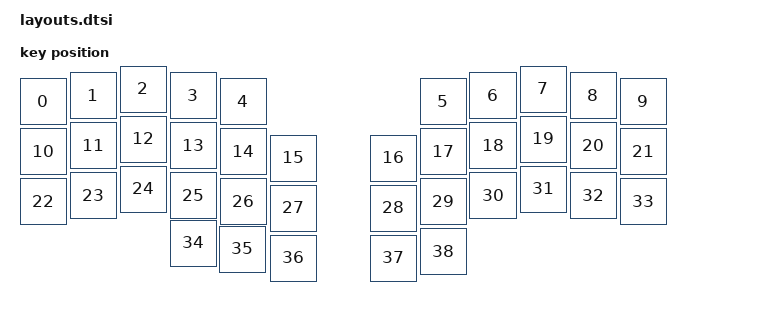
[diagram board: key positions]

#include <physical_layouts.dtsi>
/ {
    physical_layout0: physical_layout0 {
        compatible = "zmk,physical-layout";
        display-name = "Layout";
        keys
            = <&key_physical_attrs 100 100 (-50) 25 0 0 0>
			,<&key_physical_attrs 100 100 50 13 0 0 0>
			,<&key_physical_attrs 100 100 150 0 0 0 0>
			,<&key_physical_attrs 100 100 250 13 0 0 0>
			,<&key_physical_attrs 100 100 350 25 0 0 0>
			,<&key_physical_attrs 100 100 750 25 0 0 0>
			,<&key_physical_attrs 100 100 850 13 0 0 0>
			,<&key_physical_attrs 100 100 950 0 0 0 0>
			,<&key_physical_attrs 100 100 1050 13 0 0 0>
			,<&key_physical_attrs 100 100 1150 25 0 0 0>
			,<&key_physical_attrs 100 100 (-50) 125 0 0 0>
			,<&key_physical_attrs 100 100 50 113 0 0 0>
			,<&key_physical_attrs 100 100 150 100 0 0 0>
			,<&key_physical_attrs 100 100 250 113 0 0 0>
			,<&key_physical_attrs 100 100 350 125 0 0 0>
			,<&key_physical_attrs 100 100 450 138 0 0 0>
			,<&key_physical_attrs 100 100 650 138 0 0 0>
			,<&key_physical_attrs 100 100 750 125 0 0 0>
			,<&key_physical_attrs 100 100 850 113 0 0 0>
			,<&key_physical_attrs 100 100 950 100 0 0 0>
			,<&key_physical_attrs 100 100 1050 113 0 0 0>
			,<&key_physical_attrs 100 100 1150 125 0 0 0>
			,<&key_physical_attrs 100 100 (-50) 225 0 0 0>
			,<&key_physical_attrs 100 100 50 213 0 0 0>
			,<&key_physical_attrs 100 100 150 200 0 0 0>
			,<&key_physical_attrs 100 100 250 213 0 0 0>
			,<&key_physical_attrs 100 100 350 225 0 0 0>
			,<&key_physical_attrs 100 100 450 238 0 0 0>
			,<&key_physical_attrs 100 100 650 238 0 0 0>
			,<&key_physical_attrs 100 100 750 225 0 0 0>
			,<&key_physical_attrs 100 100 850 213 0 0 0>
			,<&key_physical_attrs 100 100 950 200 0 0 0>
			,<&key_physical_attrs 100 100 1050 213 0 0 0>
			,<&key_physical_attrs 100 100 1150 225 0 0 0>
			,<&key_physical_attrs 100 100 250 308 0 0 0>
			,<&key_physical_attrs 100 100 349 320 0 0 0>
			,<&key_physical_attrs 100 100 450 338 0 0 0>
			,<&key_physical_attrs 100 100 650 338 0 0 0>
			,<&key_physical_attrs 100 100 750 325 0 0 0>
            ;
    };
};
    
